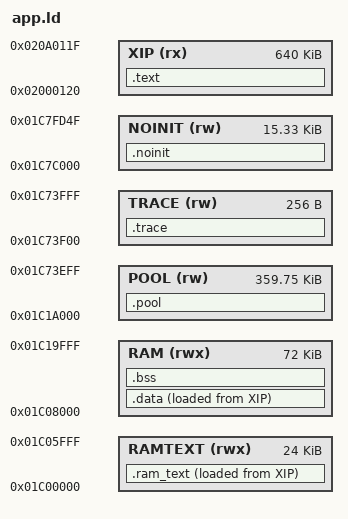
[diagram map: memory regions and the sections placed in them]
/* SPDX-License-Identifier: GPL-3.0-only
 * Copyright (C) 2026 Leo Kuroshita (@kurogedelic), Hügelton Instruments */
/* Pendel on the Pocket AMP: memory map (the FM-1 layout pendel-bsp's chip code expects).
 * XIP: code and constants run in place (app.bin offset 0 = 0x02000120).
 * RAMTEXT: .ram_text (code that runs while the flash is busy). RAM: .data / .bss, what the interrupts touch.
 * POOL: the big zero-initialised buffers (the engine's arena, the canvas, the font tables), section .pool,
 * zeroed by fm1_cstart. TRACE: the boot trace, kept across resets (main.c). Stacks above with 256-byte guard bands; NOINIT survives resets and UBOOT entry.
 * 0x01C7FD50.. is reserved (boot info, mailbox, vector table). */
MEMORY
{
    XIP    (rx)  : ORIGIN = 0x02000120, LENGTH = 0xA0000
    RAMTEXT (rwx): ORIGIN = 0x01C00000, LENGTH = 0x6000
    RAM    (rwx) : ORIGIN = 0x01C08000, LENGTH = 72K
    POOL   (rw)  : ORIGIN = 0x01C1A000, LENGTH = 0x59F00
    TRACE  (rw)  : ORIGIN = 0x01C73F00, LENGTH = 0x100   /* the boot trace: survives resets (main.c), below the stacks */
    NOINIT (rw)  : ORIGIN = 0x01C7C000, LENGTH = 0x3D50
}
SECTIONS
{
    .text : { KEEP(*(.text.crt0)) *(.text*) *(.rodata*) . = ALIGN(4); _etext = .; } > XIP
    .ram_text : { _rt_start = .; KEEP(*(.ram_text*))
                  . = ALIGN(4); _c1_start = .; KEEP(*(.c1_text*)) . = ALIGN(4); _c1_end = .;
                  _rt_end = .; } > RAMTEXT AT > XIP
    _rt_load = LOADADDR(.ram_text);
    .data : { . = ALIGN(4); _data_start = .; *(.data*) *(.sdata*) . = ALIGN(4); _data_end = .; } > RAM AT > XIP
    _data_load = LOADADDR(.data);
    .bss (NOLOAD) : { _bss_start = .; *(.bss*) *(.sbss*) *(COMMON) . = ALIGN(4); _bss_end = .; } > RAM
    .pool (NOLOAD) : { _pool_start = .; *(.pool*) . = ALIGN(4); _pool_end = .; } > POOL
    .noinit (NOLOAD) : { *(.noinit*) } > NOINIT
    .trace (NOLOAD) : { *(.trace*) } > TRACE
    _guard0 = 0x01C74000; _ustack_lo = 0x01C74100; _ustack_top = 0x01C7A000;
    _guard1 = 0x01C7A000; _sstack_lo = 0x01C7A100; _sstack_top = 0x01C7C000;
    /DISCARD/ : { *(.comment) *(.note*) }
}
